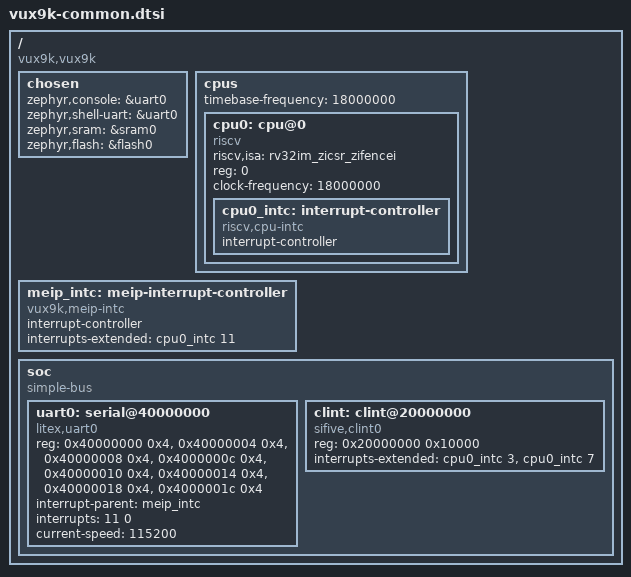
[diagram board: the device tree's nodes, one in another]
/*
 * Copyright (c) 2026 Takayuki Nagata
 * SPDX-License-Identifier: Apache-2.0
 *
 * The VUX9K SoC as soc/soc_top.veryl builds it; vux9k.dts adds the memories (the nodes
 * flash0 and sram0 under soc, in the PSRAM).
 */

#include <mem.h>

/ {
	#address-cells = <1>;
	#size-cells = <1>;
	compatible = "vux9k,vux9k";

	chosen {
		zephyr,console = &uart0;
		zephyr,shell-uart = &uart0;
		zephyr,sram = &sram0;
		zephyr,flash = &flash0;
	};

	cpus {
		#address-cells = <1>;
		#size-cells = <0>;
		timebase-frequency = <18000000>;

		cpu0: cpu@0 {
			device_type = "cpu";
			compatible = "riscv";
			riscv,isa = "rv32im_zicsr_zifencei";
			reg = <0>;
			clock-frequency = <18000000>;

			cpu0_intc: interrupt-controller {
				compatible = "riscv,cpu-intc";
				interrupt-controller;
				#address-cells = <0>;
				#interrupt-cells = <1>;
			};
		};
	};

	/*
	 * The machine external interrupt (cause 11) with two cells (irq, priority), which
	 * Zephyr's litex,uart0 driver reads (DT_INST_IRQ(0, priority)); riscv,cpu-intc has one.
	 * No driver: without CONFIG_MULTI_LEVEL_INTERRUPTS the irq cell is the cause itself.
	 */
	meip_intc: meip-interrupt-controller {
		compatible = "vux9k,meip-intc";
		interrupt-controller;
		#address-cells = <0>;
		#interrupt-cells = <2>;
		interrupts-extended = <&cpu0_intc 11>;
	};

	soc {
		#address-cells = <1>;
		#size-cells = <1>;
		compatible = "simple-bus";
		ranges;

		/*
		 * soc/uart/uart_regs.veryl: LiteX liteuart's registers, one a word. Its events
		 * are levels (TX: the TX FIFO isn't full, RX: the RX FIFO isn't empty), and
		 * EV_ENABLE & events is the machine external interrupt.
		 */
		uart0: serial@40000000 {
			compatible = "litex,uart0";
			reg = <0x40000000 0x4>, <0x40000004 0x4>, <0x40000008 0x4>, <0x4000000c 0x4>,
			      <0x40000010 0x4>, <0x40000014 0x4>, <0x40000018 0x4>, <0x4000001c 0x4>;
			reg-names = "rxtx", "txfull", "rxempty", "ev_status", "ev_pending", "ev_enable",
				    "txempty", "rxfull";
			interrupt-parent = <&meip_intc>;
			interrupts = <11 0>;
			current-speed = <115200>;
			status = "okay";
		};

		/*
		 * soc/timer_core.veryl, the CLINT (RV32 region 2): msip at +0x0, mtimecmp at
		 * +0x4000, mtime at +0xbff8, SiFive's layout, which Zephyr's riscv_machine_timer
		 * driver serves; it takes the timer interrupt from the second entry (MSI, MTI).
		 */
		clint: clint@20000000 {
			compatible = "sifive,clint0";
			reg = <0x20000000 0x10000>;
			interrupts-extended = <&cpu0_intc 3>, <&cpu0_intc 7>;
			status = "okay";
		};
	};
};
